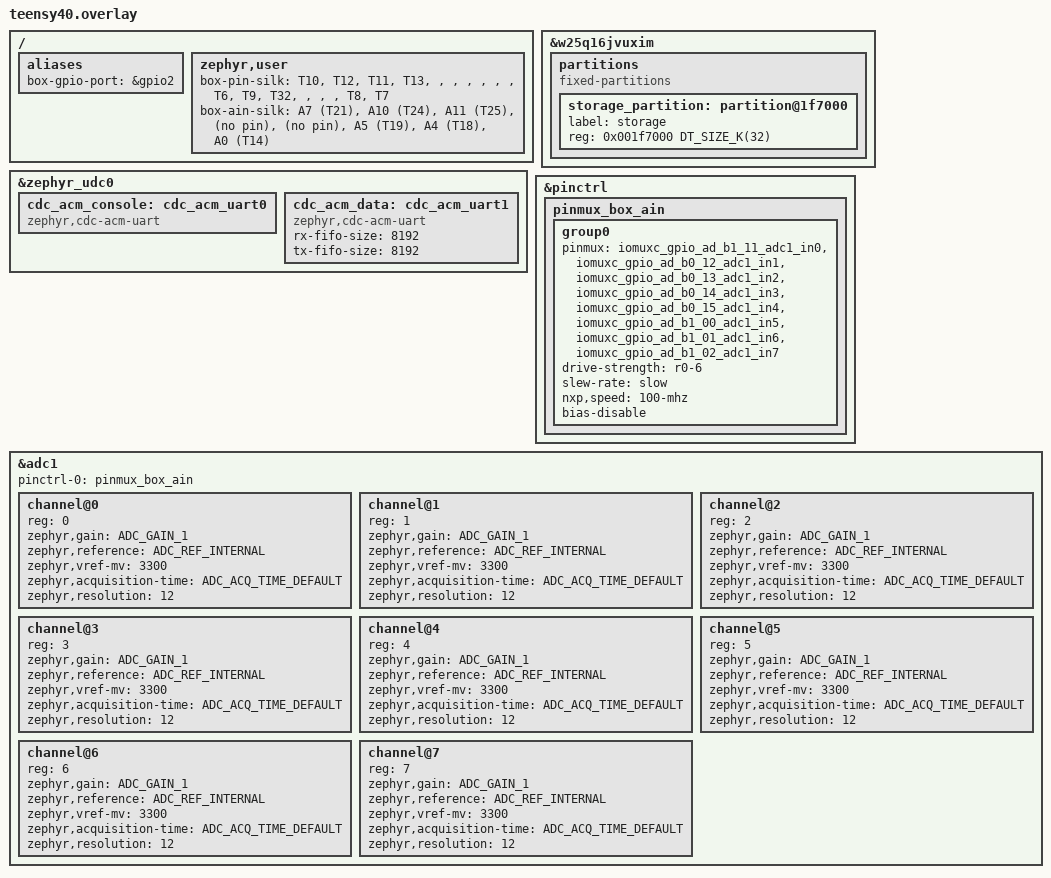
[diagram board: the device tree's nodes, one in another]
/*
 * extio-zephyr on a PJRC Teensy 4.0 (i.MX RT1062) -- the USB-only test system.
 *
 * Same silicon as the 4.1 but no Ethernet PHY, so this build is the USB-HS box:
 * a direct A/B against the Pico 2's USB-FS transport (12 Mbps vs 480 Mbps).
 * No radio, so no BLE (see boards/teensy40.conf).
 */

#include <zephyr/dt-bindings/adc/adc.h>   /* ADC_ACQ_TIME_DEFAULT */
/ {
	aliases {
		box-gpio-port     = &gpio2;   /* box pin n -> gpio2.n (3 = board LED) */
	};

	zephyr,user {
		/* ---- SILK: what is PRINTED on the board, per box pin ----
		 *
		 * Box pins here are GPIO2 bit indices, which match no marking on the
		 * board -- box pin 2 is Teensy pin 11. Without this an experimenter has
		 * to go to PINMAP.md to wire anything, and three numbering schemes are
		 * in play (box pin, SoC pad, silkscreen). Announced so the extio page
		 * can show it beside the pin number.
		 *
		 * NOT the same thing as `label N <text>`: that is a user-set ROLE
		 * ("btn_left"), persisted config, editable, and it belongs in a config
		 * dump. This is a hardware fact -- compiled in, never editable, never
		 * persisted, and deliberately absent from `dump`.
		 *
		 * Positional: index = box pin. "" where the pad is not bonded out on a
		 * 4.0 (box pins 4-9 are Teensy 40-45, which exist only on the 4.1; the
		 * 4.1 also moves its 34-37 onto B1 pads). Values are from Zephyr's own
		 * board doc (boards/pjrc/teensy4/doc/index.rst) pin->pad table crossed
		 * with the GPIO2 bank, NOT from the silkscreen -- a wrong silk label is
		 * worse than none, because it misdirects with confidence. */
		box-pin-silk = "T10","T12","T11","T13","","","","","","",
			       "T6","T9","T32","","","","T8","T7";

		/* ain channel -> what is printed. THE MOST MISLEADING MAP ON THIS
		 * BOARD: reg IS the hardware ADC input, so silkscreen A0 is channel 7,
		 * and A1 (in8) cannot be reached at all (AIN_MAX_CH is 8). */
		box-ain-silk = "A7 (T21)","A10 (T24)","A11 (T25)","(no pin)","(no pin)",
			       "A5 (T19)","A4 (T18)","A0 (T14)";
	};

	/* zephyr,console stays on lpuart6 (Teensy pins 0/1) for Zephyr's own printk
	 * and driver LOG (dev serial adapter); the box CLI shell owns the USB
	 * console CDC -- separate devices, no conflict. */
};

/* Settings storage: NVS needs a `storage_partition`, which the teensy4 board does
 * not define. Carve 32 KB near the top of the 2 MB W25Q16, far past the ~140 KB
 * app -- but NOT the last sector. See the note below; that one is not writable.
 *
 * 32 KB = EIGHT 4096-byte sectors. NVS requires a MINIMUM OF TWO (nvs_mount:
 * `sector_count < 2` -> -EINVAL) because garbage collection moves still-valid
 * entries into the next sector before erasing the previous one -- a single
 * sector has nowhere to move them. Eight is generous on a 2 MB part and gives
 * real wear headroom: the config blob is ~1076 bytes, so a 4 KB sector holds
 * only ~3 saves before GC.
 *
 * Writing the flash the chip XIP-executes from is safe here because
 * CONFIG_FLASH_MCUX_FLEXSPI_XIP=y (enabled automatically by the RT10xx SoC
 * defconfig) relocates the erase/write path to ITCM. See PORTING.md.
 *
 * 0x1f7000, NOT 0x1f8000 -- BACKED OFF BY ONE SECTOR, and that one sector is the
 * whole reason persistence never worked on this board.
 *
 * Measured on hardware 2026-08-21 with the boot-time sector scan (box_flash.c):
 * of the eight sectors in the old 0x1f8000 partition, 0-6 erased clean and
 * sector 7 -- 0x1FF000, the LAST 4 KB of the 2 MB part -- did not erase at all.
 * flash_erase() returned 0 and byte 0 still read 0x46. The chip accepts the
 * erase command for that sector and silently does nothing, which is what a
 * write-protected / reserved region looks like from software. (Consistent with
 * HalfKay preserving that region across reflashes -- PORTING.md 2026-07-23
 * noted config surviving a reflash and read it as a courtesy; it is more likely
 * that the top sector is simply not erasable.)
 *
 * NVS's failure mode from that one sector was total, not partial: nvs_mount()
 * erases as it scans, nvs_flash_erase_sector() compares the WHOLE sector after
 * erasing and returns -ENXIO when the readback is not the erase value, so
 * hitting sector 7 failed the entire mount. Every `save` then returned that
 * stored -ENXIO and the box silently reverted its whole configuration on each
 * power cycle.
 *
 * 0x1f7000 + 32 KB ends at exactly 0x1FF000, so the partition still gets its
 * eight sectors and stops one byte short of the sector that cannot be erased.
 * If you ever move this, keep the end <= 0x1FF000.
 *
 * WHY THE TEENSY41 NEVER SAW THIS, and why that made it look validated: its
 * partition is 64 KB at 0x7f0000 = 16 sectors, but box_flash.c caps NVS at
 * BOX_NVS_SECTORS (8), so NVS only ever touches 0x7f0000-0x7f8000 and the 8 MB
 * part's final sector at 0x7FF000 sits inside the partition but outside the
 * range NVS uses. The 4.1 passed by luck of geometry. This board's partition
 * was EXACTLY eight sectors, so the cap clipped nothing and the last one was in
 * play. The 4.1 needs no change -- but do not shrink its partition to 32 KB
 * without moving its base down too. */
&w25q16jvuxim {
	partitions {
		compatible = "fixed-partitions";
		#address-cells = <1>;
		#size-cells = <1>;

		storage_partition: partition@1f7000 {
			label = "storage";
			reg = <0x001f7000 DT_SIZE_K(32)>;
		};
	};
};

/* console FIRST, data SECOND -- instance order sets USB interface numbering, and
 * the dserv host module expects the data pipe at if02 / the *3 tty. See the note
 * in teensy41.overlay and README "Console status". */
&zephyr_udc0 {
	cdc_acm_console: cdc_acm_uart0 {
		compatible = "zephyr,cdc-acm-uart";
	};
	cdc_acm_data: cdc_acm_uart1 {
		compatible = "zephyr,cdc-acm-uart";
		/* the frame pipe's class-level fifos, widened to match the app
		 * rings in box_net_usb.c (8 KB): the 1024 B defaults were one
		 * of the two stages behind the ~8-frame burst cliff */
		rx-fifo-size = <8192>;
		tx-fifo-size = <8192>;
	};
};

/*
 * ---- ANALOG: the RT1062's on-chip 12-bit SAR (adc1) ----
 *
 * The Teensy was the USB-transport test system and had no analog at all; this
 * makes it a desktop analog bench too, so an eye/joystick feed can be developed
 * on a Mac without occupying the rig's MCXN947 box.
 *
 * THE CHANNEL NUMBER IS THE HARDWARE INPUT, and that is the whole constraint
 * here. Unlike the MCXN947's LPADC -- where `channel_id` indexes a CMD-register
 * slot and `zephyr,input-positive` picks the pad -- adc_mcux_12b1msps_sar writes
 * channel_id straight into ADC_HC[ADCH]. So `reg` IS the ADCn_INx number, and
 * the pad is chosen entirely by which pinmux symbol is in the group below. The
 * symbol names carry the map (`..._ad_b1_02_adc1_in7`); for this part it is:
 *
 *   in0  = AD_B1_11    in4  = AD_B0_15    in8  = AD_B1_03   in12 = AD_B1_07
 *   in1  = AD_B0_12    in5  = AD_B1_00    in9  = AD_B1_04   in13 = AD_B1_08
 *   in2  = AD_B0_13    in6  = AD_B1_01    in10 = AD_B1_05   in14 = AD_B1_09
 *   in3  = AD_B0_14    in7  = AD_B1_02    in11 = AD_B1_06   in15 = AD_B1_10
 *
 * WHY ALL EIGHT, 0-7: box_adc_sweep() refuses a mask that references a channel
 * at or above `nch` (`(mask >> nch) != 0`), and nch is just the number of
 * channel@N children. Declaring only a pair would hard-limit every future ain
 * group to channels 0-1 -- and since reg must equal the hardware input, those
 * two would be forced onto AD_B1_11 and AD_B0_12 whether or not those are the
 * pads anyone wants. Declaring 0-7 (BOX_ADC_MAX_CH / AIN_MAX_CH is 8, so 8-15
 * are unreachable by the box regardless) leaves the choice to `ain group`
 * config at runtime, which is where it belongs.
 *
 * No `box-ain-pins` property: on this board box pins are gpio2 bit indices
 * (the B0 pads), and every ADC pad is an AD_B0 or AD_B1 pad -- a different port
 * that is not in the box pin map at all. So no pad is ever shared with a
 * digital box pin,
 * every channel is a dedicated always-active input, and box_adc.c's "absent
 * pinmap" path is exactly right.
 *
 * DRIVER CONSTRAINTS, all checked in mcux_12b1msps_sar_adc_channel_setup():
 * gain must be ADC_GAIN_1, reference must be ADC_REF_INTERNAL (the driver
 * reports ref_internal = 3300, i.e. VREFH/VDDA = 3.3 V), acquisition time must
 * be ADC_ACQ_TIME_DEFAULT, and differential is rejected. Anything else fails
 * init outright rather than sampling wrong -- setup_from_dt() treats a refused
 * channel as a devicetree error and fails the whole init.
 *
 * WHICH PHYSICAL PIN each pad is remains a BOARD question -- verify against the
 * PJRC pinout card before wiring, exactly as with BTN_PIN. The AD_B0_12..15
 * inputs (in1-in4) are the A10-A13 bottom pads on a 4.0, not header pins.
 */
&pinctrl {
	pinmux_box_ain: pinmux_box_ain {
		group0 {
			pinmux = <&iomuxc_gpio_ad_b1_11_adc1_in0>,
				 <&iomuxc_gpio_ad_b0_12_adc1_in1>,
				 <&iomuxc_gpio_ad_b0_13_adc1_in2>,
				 <&iomuxc_gpio_ad_b0_14_adc1_in3>,
				 <&iomuxc_gpio_ad_b0_15_adc1_in4>,
				 <&iomuxc_gpio_ad_b1_00_adc1_in5>,
				 <&iomuxc_gpio_ad_b1_01_adc1_in6>,
				 <&iomuxc_gpio_ad_b1_02_adc1_in7>;
			drive-strength = "r0-6";
			slew-rate = "slow";
			nxp,speed = "100-mhz";
			/* NOT OPTIONAL for analog: Zephyr encodes PKE as
			 * !bias-disable (soc/nxp/imxrt/imxrt10xx/pinctrl_soc.h),
			 * so omitting this leaves the pad KEEPER on -- a weak
			 * digital latch that fights the source and compresses a
			 * pot's apparent range (the classic RT10xx analog trap;
			 * PJRC's core clears PKE for analog pins for the same
			 * reason). Found 2026-08-20 as a joystick that could not
			 * reach the rails. */
			bias-disable;
		};
	};
};

box_adc: &adc1 {
	status = "okay";
	pinctrl-0 = <&pinmux_box_ain>;
	pinctrl-names = "default";
	#address-cells = <1>;
	#size-cells = <0>;

	channel@0 { reg = <0>; zephyr,gain = "ADC_GAIN_1";
		zephyr,reference = "ADC_REF_INTERNAL"; zephyr,vref-mv = <3300>;
		zephyr,acquisition-time = <ADC_ACQ_TIME_DEFAULT>; zephyr,resolution = <12>; };
	channel@1 { reg = <1>; zephyr,gain = "ADC_GAIN_1";
		zephyr,reference = "ADC_REF_INTERNAL"; zephyr,vref-mv = <3300>;
		zephyr,acquisition-time = <ADC_ACQ_TIME_DEFAULT>; zephyr,resolution = <12>; };
	channel@2 { reg = <2>; zephyr,gain = "ADC_GAIN_1";
		zephyr,reference = "ADC_REF_INTERNAL"; zephyr,vref-mv = <3300>;
		zephyr,acquisition-time = <ADC_ACQ_TIME_DEFAULT>; zephyr,resolution = <12>; };
	channel@3 { reg = <3>; zephyr,gain = "ADC_GAIN_1";
		zephyr,reference = "ADC_REF_INTERNAL"; zephyr,vref-mv = <3300>;
		zephyr,acquisition-time = <ADC_ACQ_TIME_DEFAULT>; zephyr,resolution = <12>; };
	channel@4 { reg = <4>; zephyr,gain = "ADC_GAIN_1";
		zephyr,reference = "ADC_REF_INTERNAL"; zephyr,vref-mv = <3300>;
		zephyr,acquisition-time = <ADC_ACQ_TIME_DEFAULT>; zephyr,resolution = <12>; };
	channel@5 { reg = <5>; zephyr,gain = "ADC_GAIN_1";
		zephyr,reference = "ADC_REF_INTERNAL"; zephyr,vref-mv = <3300>;
		zephyr,acquisition-time = <ADC_ACQ_TIME_DEFAULT>; zephyr,resolution = <12>; };
	channel@6 { reg = <6>; zephyr,gain = "ADC_GAIN_1";
		zephyr,reference = "ADC_REF_INTERNAL"; zephyr,vref-mv = <3300>;
		zephyr,acquisition-time = <ADC_ACQ_TIME_DEFAULT>; zephyr,resolution = <12>; };
	channel@7 { reg = <7>; zephyr,gain = "ADC_GAIN_1";
		zephyr,reference = "ADC_REF_INTERNAL"; zephyr,vref-mv = <3300>;
		zephyr,acquisition-time = <ADC_ACQ_TIME_DEFAULT>; zephyr,resolution = <12>; };
};
